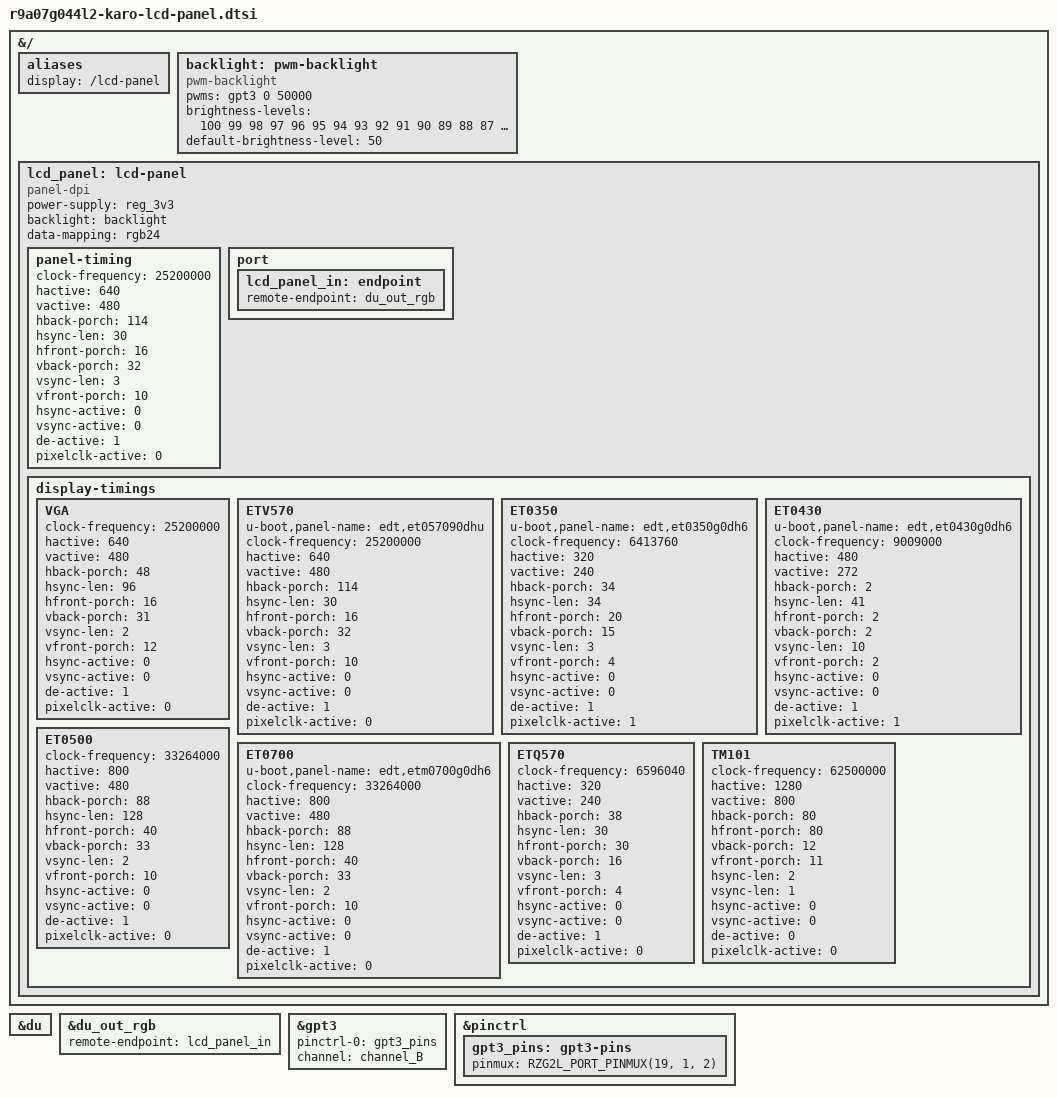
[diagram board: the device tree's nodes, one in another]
// SPDX-License-Identifier: (GPL-2.0 OR BSD-3-Clause)
/*
 * Copyright (C) 2023 Markus Bauer <MB@karo-electronics.com>
 */

#include <dt-bindings/pinctrl/rzg2l-pinctrl.h>
#include <dt-bindings/gpio/gpio.h>

&{/} {
	aliases {
		display = "/lcd-panel";
	};

	backlight: pwm-backlight {
		compatible = "pwm-backlight";
		pwms = <&gpt3 0 50000>;
		brightness-levels = <100 99 98 97 96 95 94 93 92 91
				      90 89 88 87 86 85 84 83 82 81
				      80 79 78 77 76 75 74 73 72 71
				      70 69 68 67 66 65 64 63 62 61
				      60 59 58 57 56 55 54 53 52 51
				      50 49 48 47 46 45 44 43 42 41
				      40 39 38 37 36 35 34 33 32 31
				      30 29 28 27 26 25 24 23 22 21
				      20 19 18 17 16 15 14 13 12 11
				      10  9  8  7  6  5  4  3  2  1
				       0>;
		default-brightness-level = <50>;
	};

	lcd_panel: lcd-panel {
		compatible = "panel-dpi";
		power-supply = <&reg_3v3>;
		backlight = <&backlight>;
		data-mapping = "rgb24";
		status = "okay";

		panel-timing {
			clock-frequency = <25200000>;
			hactive = <640>;
			vactive = <480>;
			hback-porch = <114>;
			hsync-len = <30>;
			hfront-porch = <16>;
			vback-porch = <32>;
			vsync-len = <3>;
			vfront-porch = <10>;
			hsync-active = <0>;
			vsync-active = <0>;
			de-active = <1>;
			pixelclk-active = <0>;
		};

		port {
			lcd_panel_in: endpoint {
				remote-endpoint = <&du_out_rgb>;
			};
		};
		
		display-timings {
			VGA: VGA {
				clock-frequency = <25200000>;
				hactive = <640>;
				vactive = <480>;
				hback-porch = <48>;
				hsync-len = <96>;
				hfront-porch = <16>;
				vback-porch = <31>;
				vsync-len = <2>;
				vfront-porch = <12>;
				hsync-active = <0>;
				vsync-active = <0>;
				de-active = <1>;
				pixelclk-active = <0>;
			};

			ETV570: ETV570 {
				u-boot,panel-name = "edt,et057090dhu";
				clock-frequency = <25200000>;
				hactive = <640>;
				vactive = <480>;
				hback-porch = <114>;
				hsync-len = <30>;
				hfront-porch = <16>;
				vback-porch = <32>;
				vsync-len = <3>;
				vfront-porch = <10>;
				hsync-active = <0>;
				vsync-active = <0>;
				de-active = <1>;
				pixelclk-active = <0>;
			};

			ET0350: ET0350 {
				u-boot,panel-name = "edt,et0350g0dh6";
				clock-frequency = <6413760>;
				hactive = <320>;
				vactive = <240>;
				hback-porch = <34>;
				hsync-len = <34>;
				hfront-porch = <20>;
				vback-porch = <15>;
				vsync-len = <3>;
				vfront-porch = <4>;
				hsync-active = <0>;
				vsync-active = <0>;
				de-active = <1>;
				pixelclk-active = <1>;
			};

			ET0430: ET0430 {
				u-boot,panel-name = "edt,et0430g0dh6";
				clock-frequency = <9009000>;
				hactive = <480>;
				vactive = <272>;
				hback-porch = <2>;
				hsync-len = <41>;
				hfront-porch = <2>;
				vback-porch = <2>;
				vsync-len = <10>;
				vfront-porch = <2>;
				hsync-active = <0>;
				vsync-active = <0>;
				de-active = <1>;
				pixelclk-active = <1>;
			};

			ET0500: ET0500 {
				clock-frequency = <33264000>;
				hactive = <800>;
				vactive = <480>;
				hback-porch = <88>;
				hsync-len = <128>;
				hfront-porch = <40>;
				vback-porch = <33>;
				vsync-len = <2>;
				vfront-porch = <10>;
				hsync-active = <0>;
				vsync-active = <0>;
				de-active = <1>;
				pixelclk-active = <0>;
			};

			ET0700: ET0700 { /* same as ET0500 */
				u-boot,panel-name = "edt,etm0700g0dh6";
				clock-frequency = <33264000>;
				hactive = <800>;
				vactive = <480>;
				hback-porch = <88>;
				hsync-len = <128>;
				hfront-porch = <40>;
				vback-porch = <33>;
				vsync-len = <2>;
				vfront-porch = <10>;
				hsync-active = <0>;
				vsync-active = <0>;
				de-active = <1>;
				pixelclk-active = <0>;
			};

			ETQ570: ETQ570 {
				clock-frequency = <6596040>;
				hactive = <320>;
				vactive = <240>;
				hback-porch = <38>;
				hsync-len = <30>;
				hfront-porch = <30>;
				vback-porch = <16>;
				vsync-len = <3>;
				vfront-porch = <4>;
				hsync-active = <0>;
				vsync-active = <0>;
				de-active = <1>;
				pixelclk-active = <0>;
			};

			TM101: TM101 {
				clock-frequency = <62500000>;
				hactive = <1280>;
				vactive = <800>;
				hback-porch = <80>;
				hfront-porch = <80>;
				vback-porch = <12>;
				vfront-porch = <11>;
				hsync-len = <2>;
				vsync-len = <1>;
				hsync-active = <0>;
				vsync-active = <0>;
				de-active = <0>;
				pixelclk-active = <0>;
			};
		};
	};
};

&du {
	status = "okay";
};

&du_out_rgb {
	remote-endpoint = <&lcd_panel_in>;
};

&gpt3 {
	pinctrl-names = "default";
	pinctrl-0 = <&gpt3_pins>;
	channel = "channel_B";
	status = "okay";
};

&pinctrl {
	gpt3_pins: gpt3-pins {
		pinmux = <RZG2L_PORT_PINMUX(19, 1, 2)>; /* Channel B */
	};
};
